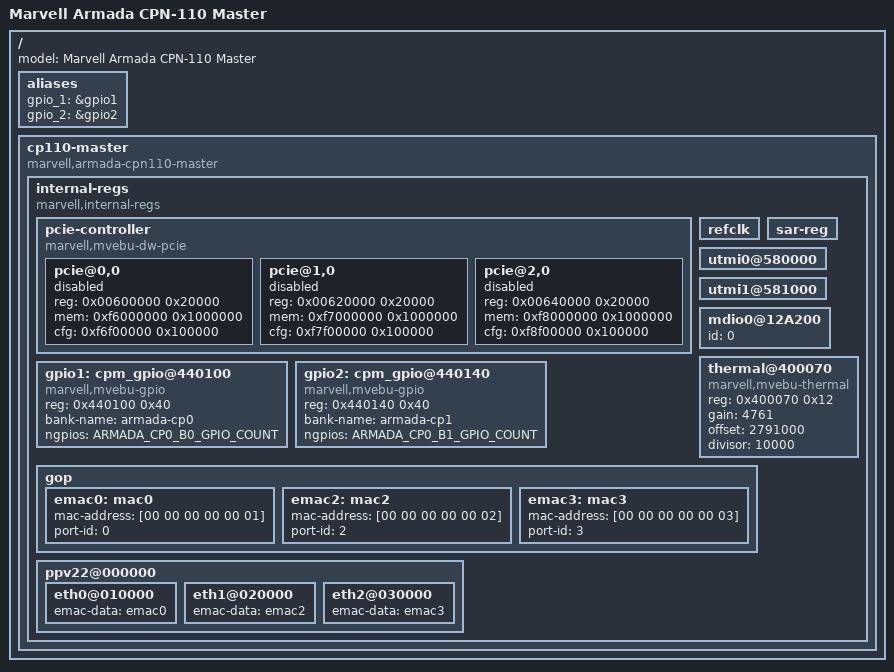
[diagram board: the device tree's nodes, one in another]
/*
 * ***************************************************************************
 * Copyright (C) 2015 Marvell International Ltd.
 * ***************************************************************************
 * This program is free software: you can redistribute it and/or modify it
 * under the terms of the GNU General Public License as published by the Free
 * Software Foundation, either version 2 of the License, or any later version.
 *
 * This program is distributed in the hope that it will be useful,
 * but WITHOUT ANY WARRANTY; without even the implied warranty of
 * MERCHANTABILITY or FITNESS FOR A PARTICULAR PURPOSE.  See the
 * GNU General Public License for more details.
 *
 * You should have received a copy of the GNU General Public License
 * along with this program.  If not, see <http://www.gnu.org/licenses/>.
 * ***************************************************************************
 */

/ {

	model = "Marvell Armada CPN-110 Master";

	aliases {
		gpio_1 = &gpio1;
		gpio_2 = &gpio2;
	};

	cp110-master {
		compatible = "marvell,armada-cpn110-master", "simple-bus";
		#address-cells = <1>;
		#size-cells = <1>;

		internal-regs {
			compatible = "marvell,internal-regs", "simple-bus";
			ranges = <0x0000 0xf2000000 0x1000000>;
			#address-cells = <1>;
			#size-cells = <1>;

			#include "cp110.dtsi"

			pcie-controller {
				#address-cells = <1>;
				#size-cells = <1>;
				compatible = "marvell,mvebu-dw-pcie";

				pcie@0,0 {
					reg = <0x00600000 0x20000>;
					mem = <0xf6000000 0x1000000>;
					cfg = <0xf6f00000 0x100000>;
					status = "disabled";
				};
				pcie@1,0 {
					reg = <0x00620000 0x20000>;
					mem = <0xf7000000 0x1000000>;
					cfg = <0xf7f00000 0x100000>;
					status = "disabled";
				};
				pcie@2,0 {
					reg = <0x00640000 0x20000>;
					mem = <0xf8000000 0x1000000>;
					cfg = <0xf8f00000 0x100000>;
					status = "disabled";
				};
			};
		};
	};

	cp110-master {
		internal-regs {
			refclk: refclk {
			};
			sar-reg {
				status = "okay";
			};
			utmi0@580000 {
				status = "okay";
			};
			utmi1@581000 {
				status = "okay";
			};
			gpio1: cpm_gpio@440100 {
				compatible = "marvell,mvebu-gpio";
				reg = <0x440100 0x40>;
				bank-name = "armada-cp0";
				ngpios = <ARMADA_CP0_B0_GPIO_COUNT>;
				status = "okay";
			};

			gpio2: cpm_gpio@440140 {
				compatible = "marvell,mvebu-gpio";
				reg = <0x440140 0x40>;
				bank-name = "armada-cp1";
				ngpios = <ARMADA_CP0_B1_GPIO_COUNT>;
				status = "okay";
			};


			mdio0@12A200 {
				id = <0>;
			};
			thermal@400070 {
				compatible = "marvell,mvebu-thermal", "marvell,thermal-sensor";
				reg = <0x400070 0x12>;
				gain = <4761>;
				offset = <2791000>;
				divisor = <10000>;
				status = "okay";
			};
			gop {
				emac0: mac0 {
					mac-address = [00 00 00 00 00 01];
					port-id = <0>; /* gop_port_id */
				};
				emac2: mac2 {
					mac-address = [00 00 00 00 00 02];
					port-id = <2>; /* gop_port_id */
				};
				emac3: mac3 {
					mac-address = [00 00 00 00 00 03];
					port-id = <3>; /* gop_port_id */
				};
			};
			ppv22@000000 {
				eth0@010000 {
					emac-data = <&emac0>;
				};
				eth1@020000 {
					emac-data = <&emac2>;
				};
				eth2@030000 {
					emac-data = <&emac3>;
				};
			};
		};
	};
};
